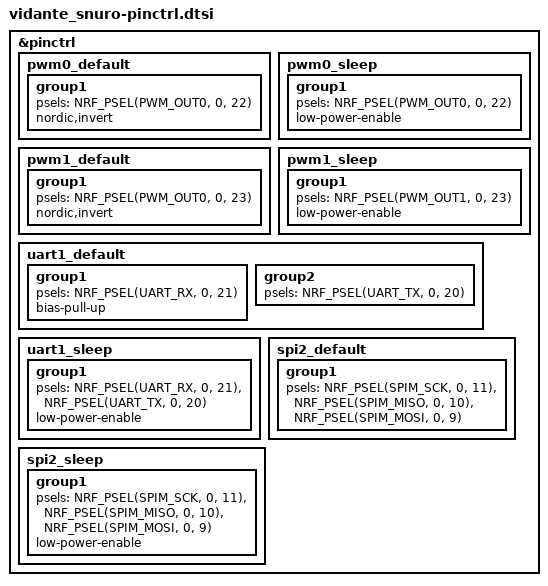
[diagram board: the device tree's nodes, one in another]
/*
 * SPDX-License-Identifier: Apache-2.0
 */

&pinctrl {
	pwm0_default: pwm0_default {
		group1 {
			/* Blue LED */
			psels = <NRF_PSEL(PWM_OUT0, 0, 22)>;
			nordic,invert;
		};
	};

	pwm0_sleep: pwm0_sleep {
		group1 {
			/* Blue LED */
			psels = <NRF_PSEL(PWM_OUT0, 0, 22)>;
			low-power-enable;
		};
	};

	pwm1_default: pwm1_default {
		group1 {
			/* Green LED */
			psels = <NRF_PSEL(PWM_OUT0, 0, 23)>;
			nordic,invert;
		};
	};

	pwm1_sleep: pwm1_sleep {
		group1 {
			/* Green LED */
			psels = <NRF_PSEL(PWM_OUT1, 0, 23)>;
			low-power-enable;
		};
	};

	uart1_default: uart1_default {
		group1 {
			psels = <NRF_PSEL(UART_RX, 0, 21)>;
			bias-pull-up;
		};
		group2 {
			psels = <NRF_PSEL(UART_TX, 0, 20)>;
		};
	};

	uart1_sleep: uart1_sleep {
		group1 {
			psels = <NRF_PSEL(UART_RX, 0, 21)>,
				<NRF_PSEL(UART_TX, 0, 20)>;
			low-power-enable;
		};
	};

	spi2_default: spi2_default {
		group1 {
			psels = <NRF_PSEL(SPIM_SCK, 0, 11)>,
				<NRF_PSEL(SPIM_MISO, 0, 10)>,
				<NRF_PSEL(SPIM_MOSI, 0, 9)>;
		};
	};

	spi2_sleep: spi2_sleep {
		group1 {
			psels = <NRF_PSEL(SPIM_SCK, 0, 11)>,
				<NRF_PSEL(SPIM_MISO, 0, 10)>,
				<NRF_PSEL(SPIM_MOSI, 0, 9)>;
			low-power-enable;
		};
	};

};
